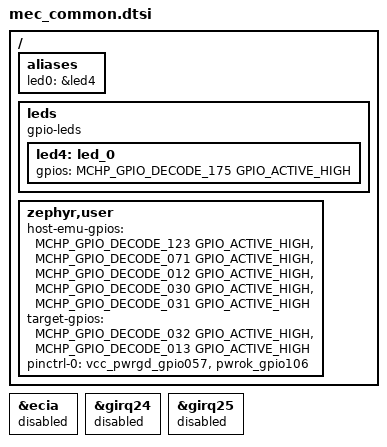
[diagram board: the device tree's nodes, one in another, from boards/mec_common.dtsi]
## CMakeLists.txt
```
# SPDX-License-Identifier: Apache-2.0

cmake_minimum_required(VERSION 3.20.0)

find_package(Zephyr REQUIRED HINTS $ENV{ZEPHYR_BASE})
project(espi_host_self_emu)

FILE(GLOB app_sources src/*.c)
target_sources(app PRIVATE ${app_sources})
```

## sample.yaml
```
sample:
  name: Exercise eSPI driver with an emulated eSPI host
tests:
  sample.boards.microchip.mec172xevb_assy6906.espi_host_self_emu:
    build_only: true
    platform_allow:
      - mec172xevb_assy6906
    tags: drivers espi spi
```

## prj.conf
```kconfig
CONFIG_LOG=y
CONFIG_LOG_MODE_IMMEDIATE=y
#CONFIG_LOG_MODE_MINIMAL=y
# !!! WARNING: deferred and buffer size not working.
# !!! log_panic() does not output messages.
#CONFIG_LOG_MODE_DEFERRED=y
#CONFIG_LOG_BUFFER_SIZE=4096
CONFIG_LOG_BACKEND_UART=y
#CONFIG_LOG_BACKEND_SWO=y
#CONFIG_LOG_BACKEND_SWO_REF_FREQ_HZ=96000000
#CONFIG_LOG_BACKEND_SWO_FREQ_HZ=4000000

CONFIG_GPIO=y
CONFIG_PINCTRL=y
CONFIG_LED=y
CONFIG_SERIAL=y
CONFIG_CONSOLE=y
CONFIG_UART_CONSOLE=y

CONFIG_SPI=y
CONFIG_SPI_XEC_QMSPI_LDMA=y
CONFIG_SPI_EXTENDED_MODES=y

#CONFIG_INTC_INIT_PRIORITY=2
#CONFIG_XEC_GIRQ_INIT_PRIORITY=3
#CONFIG_ESPI_INIT_PRIORITY=4
CONFIG_ESPI=y
CONFIG_ESPI_AUTOMATIC_WARNING_ACKNOWLEDGE=n
# CONFIG_ESPI_PERIPHERAL_HOST_IO=n

CONFIG_PM=n

# Help debug new code
# CONFIG_DEBUG_COREDUMP=y
# CONFIG_TRAP_UNALIGNED_ACCESS=y
# CONFIG_DEBUG=y
```

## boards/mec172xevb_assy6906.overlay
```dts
/*
 * Copyright (c) 2023 Microchip Technology Inc.
 *
 * SPDX-License-Identifier: Apache-2.0
 */

/* mec172xevb_assy6906 EVB with MEC1723N-SZ daughter card
 * MEC1723 does not have an internal SPI flash.
 * Connect QSPI to external shared SPI flash pins using SHD_nCS1.
 */

#include "mec_common.dtsi"

&pinctrl {
	shd_cs0_n_gpio055_sleep: shd_cs0_n_gpio055_sleep {
		pinmux = < MCHP_XEC_PINMUX(055, MCHP_AF0) >;
		low-power-enable;
	};
};

&spi0 {
	compatible = "microchip,xec-qmspi-ldma";
	status = "okay";
	pinctrl-0 = < &shd_cs0_n_gpio055_sleep
		      &shd_cs1_n_gpio002
		      &shd_clk_gpio056
		      &shd_io0_gpio223
		      &shd_io1_gpio224
		      &shd_io2_gpio227
		      &shd_io3_gpio016 >;
	pinctrl-names = "default";
};
```

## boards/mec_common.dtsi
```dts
/*
 * Copyright (c) 2023 Microchip Technology Inc.
 *
 * SPDX-License-Identifier: Apache-2.0
 */

#include <zephyr/dt-bindings/gpio/gpio.h>
#include <zephyr/dt-bindings/gpio/microchip-xec-gpio.h>
#include <microchip/mec172x/mec172xnsz-pinctrl.dtsi>

/* Sample for MEC172x EVB Assembly 6906 board with various CPU cards.
 * ------------------------------------------------------------------
 * With MEC1723N-SZ CPU card
 * EVB power !! Selected one !!
 * Selected: Jumper on JP30 5-6 selects +5V 2.1mm ID 5.5mm OD barrel connector from
 *  an external +5V power brick.
 * Jumper on J1 1-2 uses +5VCC_IN from edge connector Z1
 * Jumper on J1 3-4 uses VVD_+5V from variable voltage header
 * Jumper on J1 7-8 uses MCP2200_VBUS from MCP2200 using USB connector P2
 *
 * Voltage Rail configuration:
 * JP37 1-2, JP36 1-2, JP38 1-2 connects +3.3V_STBY to VBAT_CHIP
 * JP40 1-2 connects +3.3V_STBY to VTR selection hardware
 * JP42 1-2 connects +1.8V_STBY to VTR selection hardware
 *
 * JP41 1-2, JP43 1-2, JP39 1-2, JP44 1-2 connects VCHIP_VTR_REG to +3.3V_STBY
 *
 * JP46 1-2, JP45 1-2, JP47 1-2, connects VCHIP_VTR_PLL to +3.3V_STBY
 *
 * JP51 1-2, JP50 1-2, JP52 1-2, connects VCHIP_VTR_ANALOG to +3.3V_STBY
 *
 * JP56 1-2, JP55 1-2, JP57 1-2, connects VCHIP_VTR1 to +3.3V_STBY
 *
 * JP60 2-3, JP61 1-2, JP59 1-2, JP62 1-2, connects VCHIP_VTR2 to +1.8V_STBY
 *
 * JP65 1-2, JP63 1-2, JP66 1-2, connects VCHIP_VTR3 to +1.8V_STBY
 *
 * Straps:
 * UART_BSTRAP: JP160 1-2 pulled up to VTR1
 * CR_STRAP: JP1
 * JTAG_STRAP: JP2 2-3 pulled down via 1K
 * CMP_STRAP: JP3 2-3 pulled down via 1K
 * PWRGD_STRAP: JP4
 * VTR2_STRAP: JP5
 * BSS_STRAP: JP6 GPIO074
 * BSS_STRAP: JP7 1-2 GPIO055 pulled up to VTR2
 * CRISIS_RECOVERY_STRAP: JP152 1-2 pulled up to VTR1
 *
 * Boot-ROM GPIO055 as RSMRST#
 * GPIO Control register value = 0x0200
 * Output, push-pull, driver low, no internal pulls,
 * interrupt detection = level low, alternate out enabled.
 * ROM drives pin high(inactive) using alternate out (bit[16] of control register)
 * Control register = 0x10200
 *
 * Select GPIO057 as VCC_PWRGD input. JP21 3x6 8-9
 * Connect VCC_PWRGD to VTR1, switch S1, and U2(MCP121T-300). JP32 1-2
 * JP151 1-2 VTR1 powers VDD input of U2.
 *
 * Emulate eSPI Host using QSPI
 * JP25 1-2 connect GPIO002 to SHD_nCS1
 * JP16 14-15 connect GPIO122 to PVT_IO1
 * JP16 11-12 connect GPIO123 to PVT_IO2
 * JP115 1-2 U11 OE connected to VTR3 (enabled)
 * JP120 1-2 U13 and U14 nOE connected to VTR3 (disabled)
 *
 * QSPI SHD pins are on VTR2 set to 1.8V fly-wired to eSPI pins.
 * NOTE: keep fly-wires short or use twisted pairs.
 *   1.8V               1.8V                     +3.3V
 * SHD_nCS1 J34-10 ->  ESPI_nCS J45-1  <-> U11 <-> ESPI_nRESET_R J52-19, JP114-1
 * SHD_CLK  J34-2  ->  ESPI_CLK J45-3  <-> U11 <-> ESPI_CLK_R    J52-13
 * SHD_IO0  J34-6  <-> ESPI_IO0 J45-5  <-> U11 <-> ESPI_IO0_R    J52-7
 * SHD_IO1  J34-7  <-> ESPI_IO1 J45-7  <-> U11 <-> ESPI_IO1_R    J52-5
 * SHD_IO2  J34-8  <-> ESPI_IO2 J45-9  <-> U11 <-> ESPI_IO2_R    J52-3
 * SHD_IO3  J34-9  <-> ESPI_IO3 J45-11 <-> U11 <-> ESPI_IO3_R    J52-1
 *
 * ESPI_nRESET
 * GPIO123 J34-14 -> ESPI_nRESET_R J52-19 both VTR1
 * GPIO123 jumper for PVT_IO2. JP16 3x6 11-12. Access on J34-14
 *
 * VCC_PWRGD input
 * GPIO057 Function 1 on JP32-2 (no jumper on JP32 1-2 to disconnect power good ciruit)
 * to GPIO030 as Host drive output for VCC_PWRGD. Access on J9-1 or J40-6
 *
 * GPIO031 used as Target_nReady input to Host. Access J40-7
 *  Target uses GPIO032 on J40-8 as output
 *
 * GPIO013 used for scope measurement. JP12 3x6 7-8. Access J19-1
 *
 * Emulated Host pins
 * GPIO123 as GPIO output for driving ESPI_nRESET
 * GPIO030 as GPIO output for driving VCC_PWRGD output
 * GPIO031 as GPIO input for receiving TARGET_nREADY
 * GPIO012 as GPIO output scope trigger/measurement
 *
 * Target pins
 * GPIO057 PINCTRL function 1 as VCC_PWRGD input
 * GPIO032 as GPIO output for driving TARGET_nREADY
 * GPIO013 as GPIO output for scope trigger/measurement
 *
 * ------------------------------------------------------------------------
 * Alternative: emulate eSPI using GP-SPI controller 0. Limitations:
 * GP-SPI controllers are full-duplex or dual. Not Quad.
 * GP-SPI controller pins are all on the VTR1 domain. We must connect differntly.
 * eSPI pins are connected to bi-direction voltage translator U10. The other
 * side of U10 are ESPI_xxx_R +3.3V signals connected to header J52
 * U10 requires jumper on JP110 1-2 connecting OE to VTR3
 *
 * Wires:
 * J34 1x6
 * pin 1 VTR1
 * pin 2 SPI0_CLK to J52-13 ESPI_CLK_R
 * pin 3 SPI0_SDO to J52-7  ESPI_IO0_R
 * pin 4 SPI0_SDI to J52-5  ESPI_IO1_R
 * pin 5 SPI0_nCS to J52-9  ESPI_nCS_R
 * pin 6 GND
 *
 * J52-19 ESPI_nRESET_R to JP70-11 GPIO005
 * J52-23 ESPI_nRESET_R to JP70-17 GPIO006
 *
 * Jumpers for GPIO005, GPIO006
 * JP24: 31-32, 46-47
 * JP27: 19-20, 28-29
 * JP29: 4-5, 1-2
 *
 * Jumpers for SPI0_xxx signals
 * JP15 3x6: 2-3, 5-6, 8-9, 11-12, 17-18
 * JP85 3x4: 1-2, 4-5, 7-8, 10-11
 *
 * ------------------------------------------------------------------------
 * GPIO175/CMP_VOUT1/PWM8_ALT on schematic, LED4 on silkscreen.
 * JP19 16-17 connects GPIO175 as CMP_VOUT1
 *
 * I2C00_SDA/SCL = GPIO003/004 selection
 * Install Jumpers on JP15 4-5, JP15 7-8, JP27 31-32, JP27 34-35
 * If pull-ups on the EVB are required:
 * Install Jumper JP70 19-20 7.5K pull-up to VTR1 for I2C00_SCL
 * Install Jumper JP70 21-22 7.5K pull-up to VTR1 for I2C00_SDA
 *
 * I2C devices on EXTERNAL_SDA/SCL bus
 *
 * U4 is PCA9555 I2C GPIO expander
 * JP52 1-2 use +3.3V_STBY
 * JP61 1-2, 3-4 connects I2C00_SCL and I2C00_SDA to EXTERNAL_SCLK/SDATA
 * JP55 selects I2C address
 * 1-2 = A0, 3-4 = A1, 5-6 = A2 all pulled-up by default. Install jumper to ground signals.
 * Installed jumper on JP53 1-2. I2C Address = 0x26
 *
 * U18 is LTC2489CDE I2C 4-channel delta-sigma ADC
 * NOTE: LTC2489 is powered by +5V.
 * Address select pins CA0, CA1 both pulled high. Install jumpers to ground signals.
 * Installed jumpers on JP121 1-2 and 3-4. I2C Address = 0x34
 * VRef=3V J51 1-2
 * Channel 0 connected to Vin=2.048V JP120 1-2, J51 3-4
 */

/ {
	aliases {
		led0 = &led4;
	};

	leds {
		compatible = "gpio-leds";
		led4: led_0 {
			gpios = <MCHP_GPIO_DECODE_175 GPIO_ACTIVE_HIGH>;
		};
	};

	/* zephyr,user is a special case node for application & test use
	 * This node does not require a YAML binding file.
	 * host-emu-gpios pins
	 * index 0 = pin connected to ESPI_nRESET allowing app to control reset.
	 * index 1 = eSPI IO[1] GPIO used as eSPI ALERT. eSPI Target controller
	 * drives this pin low when it requires attention. Note: Target can drive
	 * eSPI ALERT pin when eSPI nCS is not asserted.
	 * index 2 = GPIO012 use as GPIO to help measure code sequences.
	 * index 3 = GPIO030 used as GPIO output Host-to-Target VCC_PWRGD
	 * index 4 = GPIO031 used as GPIO input Target-nReady
	 *
     * target-gpios
     * index 0 GPIO32 as GPIO output for driving TARGET_nREADY
     * index 1 GPIO13 as GPIO output for scope trigger/measurement
     *
	 * In application code use GPIO_DT_SPEC_GET_BY_IDX() macro.
	 *
	 * PINCTRL:
	 * GPIO057 configured as VCC_PWRGD input of target
	 * GPIO106 configured as PWROK output of target
	 */
	zephyr,user {
	   host-emu-gpios = <MCHP_GPIO_DECODE_123 GPIO_ACTIVE_HIGH>,
			     <MCHP_GPIO_DECODE_071 GPIO_ACTIVE_HIGH>,
			     <MCHP_GPIO_DECODE_012 GPIO_ACTIVE_HIGH>,
			     <MCHP_GPIO_DECODE_030 GPIO_ACTIVE_HIGH>,
			     <MCHP_GPIO_DECODE_031 GPIO_ACTIVE_HIGH>;
		target-gpios = <MCHP_GPIO_DECODE_032 GPIO_ACTIVE_HIGH>,
		          <MCHP_GPIO_DECODE_013 GPIO_ACTIVE_HIGH>;
		pinctrl-0 = <&vcc_pwrgd_gpio057 &pwrok_gpio106>;
		pinctrl-names = "default";
	};
};

/* Prevent Microchip XEC interrupt controller driver from loading.
 * SoC hack provides utility functions driver use to access
 * ECIA interrupt controller registers.
 */
&ecia {
    status = "disabled";
};

&girq24 {
	status = "disabled";
};

&girq25 {
	status = "disabled";
};
```

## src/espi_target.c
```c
/*
 * Copyright (c) 2024 Microchip Technology, Inc.
 *
 * SPDX-License-Identifier: Apache-2.0
 */

#include <errno.h>
#include <stdint.h>
#include <soc.h>

#include <zephyr/device.h>
#include <zephyr/devicetree.h>
#include <zephyr/kernel.h>
#include <zephyr/drivers/espi.h>
#include <zephyr/drivers/gpio.h>
#include <zephyr/drivers/pinctrl.h>
#include <zephyr/sys/sys_io.h>

#include <zephyr/logging/log_ctrl.h>
#include <zephyr/logging/log.h>
LOG_MODULE_DECLARE(app);

#include "espi_target.h"

#define ZEPHYR_USER_NODE DT_PATH(zephyr_user)
#define ESPI_NODE        DT_NODELABEL(espi0)

PINCTRL_DT_DEFINE(ZEPHYR_USER_NODE);

/* eSPI Target Thread */

#define ESPI_TARGET_THREAD_STACK_SIZE 1024
#define ESPI_TARGET_THREAD_PRIORITY   6

static void espi_target_thread(void *p1, void *p2, void *p3);
static void espi_reset_cb(const struct device *dev,
			  struct espi_callback *cb,
			  struct espi_event ev);

static void espi_chan_ready_cb(const struct device *dev,
			       struct espi_callback *cb,
			       struct espi_event ev);

static void espi_vw_received_cb(const struct device *dev,
				struct espi_callback *cb,
				struct espi_event ev);

static void espi_periph_cb(const struct device *dev,
			   struct espi_callback *cb,
			   struct espi_event ev);

K_THREAD_DEFINE(espi_target_tid, ESPI_TARGET_THREAD_STACK_SIZE, espi_target_thread, NULL, NULL,
		NULL, ESPI_TARGET_THREAD_PRIORITY, 0, 0);

const struct gpio_dt_spec target_n_ready_out_dt =
	GPIO_DT_SPEC_GET_BY_IDX(ZEPHYR_USER_NODE, target_gpios, 0);

const struct gpio_dt_spec target_debug_out_dt =
	GPIO_DT_SPEC_GET_BY_IDX(ZEPHYR_USER_NODE, target_gpios, 1);

const struct pinctrl_dev_config *app_pinctrl_cfg = PINCTRL_DT_DEV_CONFIG_GET(ZEPHYR_USER_NODE);
const struct device *espi_dev = DEVICE_DT_GET(ESPI_NODE);

struct espi_cfg ecfg;
struct espi_callback espi_cb_reset;
struct espi_callback espi_cb_chan_ready;
struct espi_callback espi_cb_vw;
struct espi_callback espi_cb_periph;

#define ESPI_CHAN_READY_PC_IDX 0
#define ESPI_CHAN_READY_VW_IDX 1
#define ESPI_CHAN_READY_OOB_IDX 2
#define ESPI_CHAN_READY_FC_IDX 3
static volatile uint8_t chan_ready[4];

int espi_target_init(uint32_t flags)
{
	struct pcr_regs *pcr = (struct pcr_regs *)0x40080100u;
	int ret = 0;

	ret = pinctrl_apply_state(app_pinctrl_cfg, PINCTRL_STATE_DEFAULT);
	if (ret) {
		LOG_ERR("eSPI target init state apply: %d", ret);
		return -EIO;
	}

	if (!device_is_ready(espi_dev)) {
		LOG_ERR("eSPI target controller not ready!");
		return -EIO;
	}

	ret = gpio_pin_configure_dt(&target_n_ready_out_dt, GPIO_OUTPUT_HIGH);
	if (ret) {
		LOG_ERR("Target nReady out pin config error (%d)", ret);
		return -EIO;
	}

	ret = gpio_pin_configure_dt(&target_debug_out_dt, GPIO_OUTPUT_HIGH);
	if (ret) {
		LOG_ERR("Target debug out pin config error (%d)", ret);
		return -EIO;
	}

	/* PCR enable VCC_PWRGD input and select Platform reset signal to be eSPI
	 * PLTRST# virtual wire.
	 */
	pcr->PWR_RST_CTRL &= (uint32_t)~MCHP_PCR_PR_CTRL_MASK;

	ecfg.io_caps = ESPI_IO_MODE_SINGLE_LINE;
	ecfg.channel_caps = (ESPI_CHANNEL_PERIPHERAL | ESPI_CHANNEL_VWIRE | ESPI_CHANNEL_OOB |
			     ESPI_CHANNEL_FLASH);
	ecfg.max_freq = 20u;
	ret = espi_config(espi_dev, &ecfg);
	if (ret) {
		LOG_ERR("eSPI driver config error (%d)", ret);
		return ret;
	}

	/* register eSPI event callbacks */
	espi_cb_reset.handler = espi_reset_cb;
	espi_cb_reset.evt_type = ESPI_BUS_RESET;
	ret = espi_add_callback(espi_dev, &espi_cb_reset);
	if (ret) {
		LOG_ERR("Add callback for eSPI Reset (%d)", ret);
		return ret;
	}

	espi_cb_chan_ready.handler = espi_chan_ready_cb;
	espi_cb_chan_ready.evt_type = ESPI_BUS_EVENT_CHANNEL_READY;
	ret = espi_add_callback(espi_dev, &espi_cb_chan_ready);
	if (ret) {
		LOG_ERR("Add callback for eSPI channel ready (%d)", ret);
		return ret;
	}

	espi_cb_vw.handler = espi_vw_received_cb;
	espi_cb_vw.evt_type = ESPI_BUS_EVENT_VWIRE_RECEIVED;
	ret = espi_add_callback(espi_dev, &espi_cb_vw);
	if (ret) {
		LOG_ERR("Add callback for VW received (%d)", ret);
	}

	espi_cb_periph.handler = espi_periph_cb;
	espi_cb_periph.evt_type = ESPI_BUS_PERIPHERAL_NOTIFICATION;
	ret = espi_add_callback(espi_dev, &espi_cb_periph);
	if (ret) {
		LOG_ERR("Add callback for peripheral channel (%d)", ret);
	}

	return 0;
}

static void espi_reset_cb(const struct device *dev,
			  struct espi_callback *cb,
			  struct espi_event ev)
{
	LOG_INF("eSPI_nRESET CB: %u", ev.evt_data);
}

static void espi_chan_ready_cb(const struct device *dev,
			       struct espi_callback *cb,
			       struct espi_event ev)
{
	switch (ev.evt_details) {
	case ESPI_CHANNEL_VWIRE:
		chan_ready[ESPI_CHAN_READY_VW_IDX] = ev.evt_data & 0xffu;
		LOG_INF("eSPI Host set VW enable = %u", ev.evt_data);
		break;
	case ESPI_CHANNEL_PERIPHERAL:
		chan_ready[ESPI_CHAN_READY_PC_IDX] = ev.evt_data & 0xffu;
		LOG_INF("eSPI Host set PC enable = %u", ev.evt_data);
		break;
	case ESPI_CHANNEL_OOB:
		chan_ready[ESPI_CHAN_READY_OOB_IDX] = ev.evt_data & 0xffu;
		LOG_INF("eSPI Host set OOB enable = %u", ev.evt_data);
		break;
	case ESPI_CHANNEL_FLASH:
		chan_ready[ESPI_CHAN_READY_FC_IDX] = ev.evt_data & 0xffu;
		LOG_INF("eSPI Host set FC enable = %u", ev.evt_data);
		break;
	default:
		LOG_ERR("eSPI Chan Enable unknown: %u", ev.evt_details);
	}
}

static void espi_vw_received_cb(const struct device *dev,
				struct espi_callback *cb,
				struct espi_event ev)
{
	LOG_INF("eSPI CB: VW received: %u 0x%x 0x%x",
		ev.evt_type, ev.evt_data, ev.evt_details);
}

static void espi_periph_cb(const struct device *dev,
			   struct espi_callback *cb,
			   struct espi_event ev)
{
	LOG_INF("eSPI CB: PC: %u 0x%x 0x%x", ev.evt_type, ev.evt_data, ev.evt_details);
}

static void espi_target_thread(void *p1, void *p2, void *p3)
{
	uint32_t state = 0;
	bool vw_en = false;
	bool pc_en = false;
	bool oob_en = false;
	bool fc_en = false;

	LOG_INF("eSPI Target Thread Entry: Signal Host the Target is ready");

	gpio_pin_set_dt(&target_n_ready_out_dt, 0);
	k_sleep(K_MSEC(100));

	while (1) { /* check host events */
		switch (state) {
		case 0:
			vw_en = espi_get_channel_status(espi_dev, ESPI_CHANNEL_VWIRE);
			pc_en = espi_get_channel_status(espi_dev, ESPI_CHANNEL_PERIPHERAL);
			oob_en = espi_get_channel_status(espi_dev, ESPI_CHANNEL_OOB);
			if (!fc_en && espi_get_channel_status(espi_dev, ESPI_CHANNEL_FLASH)) {
				espi_send_vwire(espi_dev, ESPI_VWIRE_SIGNAL_TARGET_BOOT_STS, 1);
				espi_send_vwire(espi_dev, ESPI_VWIRE_SIGNAL_TARGET_BOOT_DONE, 1);
				state = 1;
				LOG_INF("Set TC VWires Boot Status and Done = 1");
			}
			k_sleep(K_MSEC(100));
			break;
		case 1:
			k_sleep(K_MSEC(1000));
			break;
		case 2:
			k_sleep(K_MSEC(1000));
			break;
		default:
			state = 0;
		}
	}
}
```

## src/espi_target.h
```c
#ifndef __SAMPLES_BOARDS_MICROCHIP_MEC172XEVB_ASSY6906_ESPI_HOST_SELF_EMU_ESPI_TARGET_H_
#define __SAMPLES_BOARDS_MICROCHIP_MEC172XEVB_ASSY6906_ESPI_HOST_SELF_EMU_ESPI_TARGET_H_

#include <stdint.h>
#include <stddef.h>

int espi_target_init(uint32_t flags);
void espi_target_thread_entry(void *p1, void *p2, void *p3);

#endif /* __SAMPLES_BOARDS_MICROCHIP_MEC172XEVB_ASSY6906_ESPI_HOST_SELF_EMU_ESPI_TARGET_H_ */
```
